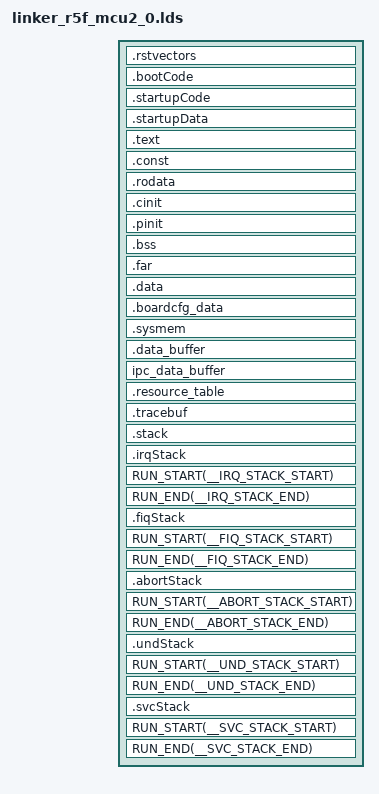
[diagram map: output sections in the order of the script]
/* Linker Settings */
--retain="*(.bootCode)"
--retain="*(.startupCode)"
--retain="*(.startupData)"
--retain="*(.intvecs)"
--retain="*(.intc_text)"
--retain="*(.rstvectors)"
--retain="*(.irqStack)"
--retain="*(.fiqStack)"
--retain="*(.abortStack)"
--retain="*(.undStack)"
--retain="*(.svcStack)"
--fill_value=0
--stack_size=0x2000
--heap_size=0x1000
--entry_point=_resetvectors     /* Default C RTS boot.asm   */

-stack  0x2000                              /* SOFTWARE STACK SIZE           */
-heap   0x2000                              /* HEAP AREA SIZE                */

/* Stack Sizes for various modes */
__IRQ_STACK_SIZE = 0x1000;
__FIQ_STACK_SIZE = 0x1000;
__ABORT_STACK_SIZE = 0x1000;
__UND_STACK_SIZE = 0x1000;
__SVC_STACK_SIZE = 0x1000;

#define DDR0_ALLOCATED_START 0xA0000000

#define MCU1_0_EXT_DATA_BASE     (DDR0_ALLOCATED_START + 0x00100000)
#define MCU1_0_R5F_MEM_TEXT_BASE (DDR0_ALLOCATED_START + 0x00200000)
#define MCU1_0_R5F_MEM_DATA_BASE (DDR0_ALLOCATED_START + 0x00300000)
#define MCU1_0_DDR_SPACE_BASE    (DDR0_ALLOCATED_START + 0x00400000)

#define MCU1_1_ALLOCATED_START   DDR0_ALLOCATED_START + 0x01000000
#define MCU1_1_EXT_DATA_BASE     (MCU1_1_ALLOCATED_START + 0x00100000)
#define MCU1_1_R5F_MEM_TEXT_BASE (MCU1_1_ALLOCATED_START + 0x00200000)
#define MCU1_1_R5F_MEM_DATA_BASE (MCU1_1_ALLOCATED_START + 0x00300000)
#define MCU1_1_DDR_SPACE_BASE    (MCU1_1_ALLOCATED_START + 0x00400000)

#define MCU2_0_ALLOCATED_START   DDR0_ALLOCATED_START + 0x02000000
#define MCU2_0_EXT_DATA_BASE     (MCU2_0_ALLOCATED_START + 0x00100000)
#define MCU2_0_R5F_MEM_TEXT_BASE (MCU2_0_ALLOCATED_START + 0x00200000)
#define MCU2_0_R5F_MEM_DATA_BASE (MCU2_0_ALLOCATED_START + 0x00300000)
#define MCU2_0_DDR_SPACE_BASE    (MCU2_0_ALLOCATED_START + 0x00400000)

#define MCU2_1_ALLOCATED_START   DDR0_ALLOCATED_START + 0x03000000
#define MCU2_1_EXT_DATA_BASE     (MCU2_1_ALLOCATED_START + 0x00100000)
#define MCU2_1_R5F_MEM_TEXT_BASE (MCU2_1_ALLOCATED_START + 0x00200000)
#define MCU2_1_R5F_MEM_DATA_BASE (MCU2_1_ALLOCATED_START + 0x00300000)
#define MCU2_1_DDR_SPACE_BASE    (MCU2_1_ALLOCATED_START + 0x00400000)

#define ATCM_START 0x00000000
#define OCMRAM_MCU1_0_START 0x41cfe000
#define OCMRAM_MCU1_1_START 0x41cff000

/* Memory Map */
MEMORY
{
/*    VECTORS (X)             : origin=0x41C7F000 length=0x1000 */
    /*  Reset Vectors base address(RESET_VECTORS) should be 64 bytes aligned  */
    RESET_VECTORS (X)       : origin=0x0 length=0x100
    /* MCU0_R5F_0 local view */
    MCU0_R5F_TCMA (X)       : origin=0x100      length=0x8000 - 0x100
    MCU0_R5F_TCMB0 (RWIX)   : origin=0x41010000 length=0x8000

    /* MCU0_R5F_1 SoC view */
    MCU0_R5F1_ATCM (RWIX)   : origin=0x41400000 length=0x8000
    MCU0_R5F1_BTCM (RWIX)   : origin=0x41410000 length=0x8000

    /* MCU0 share locations */
    OCMRAM  (RWIX)          : origin=0x41C00100 length=0x80000 - 0x1100      /* ~510KB */

    /* j721e MCMS3 locations */
    /* j721e Reserved Memory for ARM Trusted Firmware */
    MSMC3_ARM_FW   (RWIX)   : origin=0x70000000 length=0x20000         /* 128KB */
    MSMC3   (RWIX)          : origin=0x70020000 length=0x7D0000        /* 8MB - 192KB */
    /* j721e Reserved Memory for DMSC Firmware */
    MSMC3_DMSC_FW  (RWIX)   : origin=0x707F0000 length=0x10000         /* 64KB */

    DDR0_RESERVED    (RWIX)  	: origin=0x80000000 length=0x20000000	  	/* 512MB */
    MCU1_0_IPC_DATA (RWIX)	: origin=DDR0_ALLOCATED_START     length=0x00100000	/*   1MB */
    MCU1_0_EXT_DATA  (RWIX)	: origin=MCU1_0_EXT_DATA_BASE     length=0x00100000	/*   1MB */
    MCU1_0_R5F_MEM_TEXT (RWIX)	: origin=MCU1_0_R5F_MEM_TEXT_BASE length=0x00100000	/*   1MB */
    MCU1_0_R5F_MEM_DATA (RWIX)	: origin=MCU1_0_R5F_MEM_DATA_BASE length=0x00100000	/*   1MB */
    MCU1_0_DDR_SPACE (RWIX)	: origin=MCU1_0_DDR_SPACE_BASE    length=0x00C00000	/*  12MB */
    MCU1_1_IPC_DATA (RWIX)	: origin=MCU1_1_ALLOCATED_START   length=0x00100000	/*   1MB */
    MCU1_1_EXT_DATA  (RWIX)	: origin=MCU1_1_EXT_DATA_BASE     length=0x00100000	/*   1MB */
    MCU1_1_R5F_MEM_TEXT (RWIX)	: origin=MCU1_1_R5F_MEM_TEXT_BASE length=0x00100000	/*   1MB */
    MCU1_1_R5F_MEM_DATA (RWIX)	: origin=MCU1_1_R5F_MEM_DATA_BASE length=0x00100000	/*   1MB */
    MCU1_1_DDR_SPACE (RWIX)	: origin=MCU1_1_DDR_SPACE_BASE    length=0x00C00000	/*  12MB */
    MCU2_0_IPC_DATA (RWIX)	: origin=MCU2_0_ALLOCATED_START   length=0x00100000	/*   1MB */
    MCU2_0_EXT_DATA  (RWIX)	: origin=MCU2_0_EXT_DATA_BASE     length=0x00100000	/*   1MB */
    MCU2_0_R5F_MEM_TEXT (RWIX)	: origin=MCU2_0_R5F_MEM_TEXT_BASE length=0x00100000	/*   1MB */
    MCU2_0_R5F_MEM_DATA (RWIX)	: origin=MCU2_0_R5F_MEM_DATA_BASE length=0x00100000	/*   1MB */
    MCU2_0_DDR_SPACE (RWIX)	: origin=MCU2_0_DDR_SPACE_BASE    length=0x00C00000	/*  12MB */
    MCU2_1_IPC_DATA (RWIX)	: origin=MCU2_1_ALLOCATED_START   length=0x00100000	/*   1MB */
    MCU2_1_EXT_DATA  (RWIX)	: origin=MCU2_1_EXT_DATA_BASE     length=0x00100000	/*   1MB */
    MCU2_1_R5F_MEM_TEXT (RWIX)	: origin=MCU2_1_R5F_MEM_TEXT_BASE length=0x00100000	/*   1MB */
    MCU2_1_R5F_MEM_DATA (RWIX)	: origin=MCU2_1_R5F_MEM_DATA_BASE length=0x00100000	/*   1MB */
    MCU2_1_DDR_SPACE (RWIX)	: origin=MCU2_1_DDR_SPACE_BASE    length=0x00C00000	/*  12MB */
}

/* Section Configuration */
SECTIONS
{
    /* 'intvecs' and 'intc_text' sections shall be placed within */
    /* a range of +\- 16 MB */
/*    .intvecs       : {} palign(8)      > VECTORS
    .intc_text     : {} palign(8)      > VECTORS */
    .rstvectors    : {} palign(8)      > RESET_VECTORS
    .bootCode      : {} palign(8)      > MCU0_R5F_TCMA
    .startupCode   : {} palign(8)      > MCU0_R5F_TCMA
    .startupData   : {} palign(8)      > MCU0_R5F_TCMA, type = NOINIT
    .text          : {} palign(8)      > MCU2_0_DDR_SPACE
    .const         : {} palign(8)      > MCU2_0_DDR_SPACE
    .rodata         : {} palign(8)      > MCU2_0_DDR_SPACE
    .cinit         : {} palign(8)      > MCU2_0_DDR_SPACE
    .pinit         : {} palign(8)      > MCU2_0_DDR_SPACE
    .bss           : {} align(4)       > MCU2_0_DDR_SPACE
    .far           : {} align(4)       > MCU2_0_DDR_SPACE
    .data          : {} palign(128)    > MCU2_0_DDR_SPACE
    .boardcfg_data : {} palign(128)    > MCU2_0_DDR_SPACE
    .sysmem        : {}                > MCU2_0_DDR_SPACE
    .data_buffer   : {} palign(128)    > MCU2_0_DDR_SPACE

    /* USB or any other LLD buffer for benchmarking */
    .benchmark_buffer (NOLOAD) {} ALIGN (8) > MCU2_0_DDR_SPACE
    ipc_data_buffer (NOINIT) : {} palign(128)	> MCU2_0_DDR_SPACE
    .resource_table : {
        __RESOURCE_TABLE = .;
    } > MCU2_0_EXT_DATA_BASE

    .tracebuf   : {}	align(1024) > MCU2_0_EXT_DATA

    .stack      : {} align(4)       > MCU2_0_DDR_SPACE  (HIGH)
    .irqStack   : {. = . + __IRQ_STACK_SIZE;} align(4)      > MCU2_0_DDR_SPACE  (HIGH)
    RUN_START(__IRQ_STACK_START)
    RUN_END(__IRQ_STACK_END)
    .fiqStack   : {. = . + __FIQ_STACK_SIZE;} align(4)      > MCU2_0_DDR_SPACE  (HIGH)
    RUN_START(__FIQ_STACK_START)
    RUN_END(__FIQ_STACK_END)
    .abortStack : {. = . + __ABORT_STACK_SIZE;} align(4)    > MCU2_0_DDR_SPACE  (HIGH)
    RUN_START(__ABORT_STACK_START)
    RUN_END(__ABORT_STACK_END)
    .undStack   : {. = . + __UND_STACK_SIZE;} align(4)      > MCU2_0_DDR_SPACE  (HIGH)
    RUN_START(__UND_STACK_START)
    RUN_END(__UND_STACK_END)
    .svcStack   : {. = . + __SVC_STACK_SIZE;} align(4)      > MCU2_0_DDR_SPACE  (HIGH)
    RUN_START(__SVC_STACK_START)
    RUN_END(__SVC_STACK_END)
}
